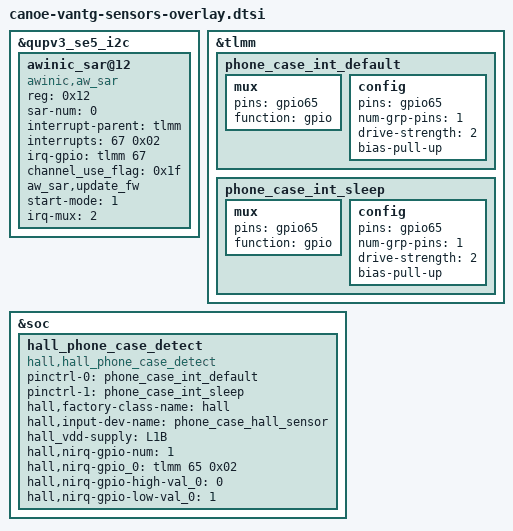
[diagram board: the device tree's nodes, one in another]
/*
 * Copyright (c) 2023, The Linux Foundation. All rights reserved.
 *
 * This program is free software; you can redistribute it and/or modify
 * it under the terms of the GNU General Public License version 2 and
 * only version 2 as published by the Free Software Foundation.
 *
 * This program is distributed in the hope that it will be useful,
 * but WITHOUT ANY WARRANTY; without even the implied warranty of
 * MERCHANTABILITY or FITNESS FOR A PARTICULAR PURPOSE.  See the
 * GNU General Public License for more details.
 */

&qupv3_se5_i2c {
        status = "okay";
        awinic_sar@12 {
                /* common node */
                compatible = "awinic,aw_sar";
                reg = < 0x12 >;
                //aw_sar,regulator-power-supply = <1>;
                sar-num = < 0 >;
                interrupt-parent = < &tlmm >;
                interrupts = <67 0x02>;
                interrupt-names = "awinic_irq";
                irq-gpio = <&tlmm 67 0x02>;
                //vcc0-supply = <&L12A>;
                channel_use_flag = <0x1f>;
                //aw_sar,use_plug_cail;
                aw_sar,update_fw;
                /* private node belongs to aw963xx */
                start-mode = < 1 >; // 0: start in rom  1: start in ram
                irq-mux = < 2 >; // set csx as irq pin. config this field when connect to aw96308/aw96310
                status = "okay";
        };


};

&tlmm {
	phone_case_int_default: phone_case_int_default {
			mux {
				pins = "gpio65";
				function =  "gpio";
			};
			config {
				pins = "gpio65";
				num-grp-pins = <1>;
				drive-strength = <2>;
				bias-pull-up;
			};
	};

	phone_case_int_sleep: phone_case_int_sleep {
			mux {
				pins = "gpio65";
				function =  "gpio";
			};
			config {
				pins = "gpio65";
				num-grp-pins = <1>;
				drive-strength = <2>;
				bias-pull-up;
			};
	};
};

&soc {
	hall_phone_case_detect {
		compatible = "hall,hall_phone_case_detect";
		pinctrl-names = "default","sleep";
		pinctrl-0 = <&phone_case_int_default>;
		pinctrl-1 = <&phone_case_int_sleep>;
		hall,factory-class-name = "hall";
		hall,input-dev-name = "phone_case_hall_sensor";
		hall_vdd-supply = <&L1B>;
		hall,nirq-gpio-num = <1>;
		hall,nirq-gpio_0 = <&tlmm 65 0x02>;
		hall,nirq-gpio-high-val_0 = <0>;
		hall,nirq-gpio-low-val_0 = <1>;
	};
};
